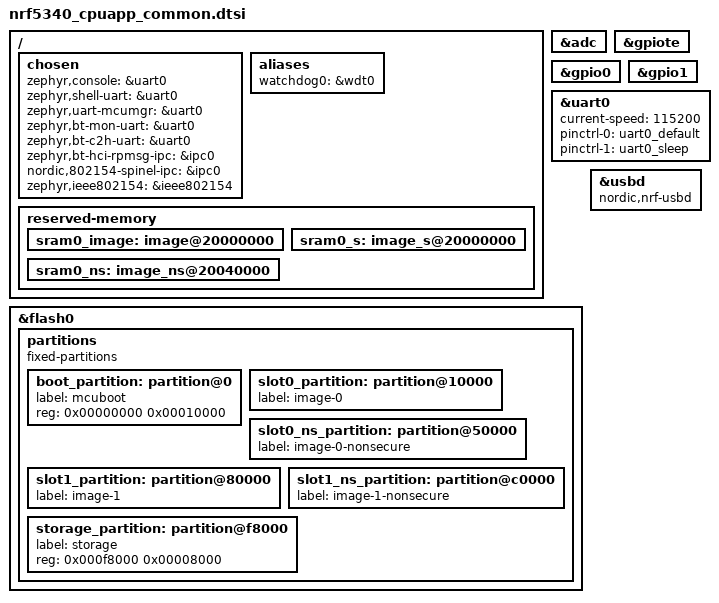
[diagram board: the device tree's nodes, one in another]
/*
 * Copyright (c) 2019-2020 Nordic Semiconductor ASA
 *
 * SPDX-License-Identifier: Apache-2.0
 */
#include "nrf5340_cpuapp_common-pinctrl.dtsi"
#include <zephyr/dt-bindings/input/input-event-codes.h>

/ {

	chosen {
		zephyr,console = &uart0;
		zephyr,shell-uart = &uart0;
		zephyr,uart-mcumgr = &uart0;
		zephyr,bt-mon-uart = &uart0;
		zephyr,bt-c2h-uart = &uart0;
		zephyr,bt-hci-rpmsg-ipc = &ipc0;
		nordic,802154-spinel-ipc = &ipc0;
		zephyr,ieee802154 = &ieee802154;
	};

	// leds {
	// 	compatible = "gpio-leds";
	// 	led0: led_0 {
	// 		gpios = <&gpio0 28 GPIO_ACTIVE_LOW>;
	// 		label = "Green LED 0";
	// 	};
	// 	led1: led_1 {
	// 		gpios = <&gpio0 29 GPIO_ACTIVE_LOW>;
	// 		label = "Green LED 1";
	// 	};
	// 	led2: led_2 {
	// 		gpios = <&gpio0 30 GPIO_ACTIVE_LOW>;
	// 		label = "Green LED 2";
	// 	};
	// 	led3: led_3 {
	// 		gpios = <&gpio0 31 GPIO_ACTIVE_LOW>;
	// 		label = "Green LED 3";
	// 	};
	// };

	// buttons {
	// 	compatible = "gpio-keys";
	// 	button0: button_0 {
	// 		gpios = <&gpio0 23 (GPIO_PULL_UP | GPIO_ACTIVE_LOW)>;
	// 		label = "Push button 1";
	// 		zephyr,code = <INPUT_KEY_0>;
	// 	};
	// 	button1: button_1 {
	// 		gpios = <&gpio0 24 (GPIO_PULL_UP | GPIO_ACTIVE_LOW)>;
	// 		label = "Push button 2";
	// 		zephyr,code = <INPUT_KEY_1>;
	// 	};
	// 	button2: button_2 {
	// 		gpios = <&gpio0 8 (GPIO_PULL_UP | GPIO_ACTIVE_LOW)>;
	// 		label = "Push button 3";
	// 		zephyr,code = <INPUT_KEY_2>;
	// 	};
	// 	button3: button_3 {
	// 		gpios = <&gpio0 9 (GPIO_PULL_UP | GPIO_ACTIVE_LOW)>;
	// 		label = "Push button 4";
	// 		zephyr,code = <INPUT_KEY_3>;
	// 	};
	// };

	// gpio_fwd: nrf-gpio-forwarder {
	// 	compatible = "nordic,nrf-gpio-forwarder";
	// 	status = "okay";
	// 	uart {
	// 		gpios = <&gpio1 1 0>, <&gpio1 0 0>, <&gpio0 11 0>, <&gpio0 10 0>;
	// 	};


	// 	nrf21540-gpio-if {
	// 		gpios = <&arduino_header 11 0>,		/* tx-en-gpios */
	// 			<&arduino_header 9 0>,		/* rx-en-gpios */
	// 			<&arduino_header 15 0>,		/* pdn-gpios */
	// 			<&arduino_header 10 0>,		/* ant-sel-gpios */
	// 			<&arduino_header 8 0>;		/* mode-gpios */
	// 	};
	// 	nrf21540-spi-if {
	// 		gpios = <&arduino_header 16 0>,		/* cs-gpios */
	// 			<&gpio1 15 0>,			/* SPIM_SCK */
	// 			<&gpio1 14 0>,			/* SPIM_MISO */
	// 			<&gpio1 13 0>;			/* SPIM_MOSI */
	// 	};
	// };

	// nrf_radio_fem: nrf21540_fem {
	// 	compatible = "nordic,nrf21540-fem";
	// 	tx-en-gpios = <&arduino_header 11 GPIO_ACTIVE_HIGH>;   /* D5 */
	// 	rx-en-gpios = <&arduino_header 9 GPIO_ACTIVE_HIGH>;    /* D3 */
	// 	pdn-gpios = <&arduino_header 15 GPIO_ACTIVE_HIGH>;     /* D9 */
	// 	ant-sel-gpios = <&arduino_header 10 GPIO_ACTIVE_HIGH>; /* D4 */
	// 	mode-gpios = <&arduino_header 8 GPIO_ACTIVE_HIGH>;     /* D2 */
	// 	// spi-if = <&nrf_radio_fem_spi>;
	// 	supply-voltage-mv = <3000>;
	// };

	/* These aliases are provided for compatibility with samples */
	aliases {
		// led0 = &led0;
		// led1 = &led1;
		// led2 = &led2;
		// led3 = &led3;
		// sw0 = &button0;
		// sw1 = &button1;
		// sw2 = &button2;
		// sw3 = &button3;
		watchdog0 = &wdt0;
	};
};

&adc {
	status = "okay";
};

&gpiote {
	status = "okay";
};

&gpio0 {
	status = "okay";
};

&gpio1 {
	status = "okay";
};

&uart0 {
	status = "okay";
	current-speed = <115200>;
	pinctrl-0 = <&uart0_default>;
	pinctrl-1 = <&uart0_sleep>;
	pinctrl-names = "default", "sleep";
};

&flash0 {

	partitions {
		compatible = "fixed-partitions";
		#address-cells = <1>;
		#size-cells = <1>;

		boot_partition: partition@0 {
			label = "mcuboot";
			reg = <0x00000000 0x00010000>;
		};
		slot0_partition: partition@10000 {
			label = "image-0";
		};
		slot0_ns_partition: partition@50000 {
			label = "image-0-nonsecure";
		};
		slot1_partition: partition@80000 {
			label = "image-1";
		};
		slot1_ns_partition: partition@c0000 {
			label = "image-1-nonsecure";
		};
		/* 0xf0000 to 0xf7fff reserved for TF-M partitions */
		storage_partition: partition@f8000 {
			label = "storage";
			reg = <0x000f8000 0x00008000>;
		};
	};
};

zephyr_udc0: &usbd {
	compatible = "nordic,nrf-usbd";
	status = "okay";
};

/ {

	reserved-memory {
		#address-cells = <1>;
		#size-cells = <1>;
		ranges;

		sram0_image: image@20000000 {
			/* Zephyr image(s) memory */
		};

		sram0_s: image_s@20000000 {
			/* Secure image memory */
		};

		sram0_ns: image_ns@20040000 {
			/* Non-Secure image memory */
		};
	};
};

/* Include partition configuration file */
#include "nrf5340_cpuapp_partition_conf.dtsi"
